# CY8C5868AXI_LP032 register map
File version: 0.1
CY8C58LP
Registers are 8-bit, read-write, no defined reset value unless marked. A register's access mark holds for its fields unless they carry their own. Offsets are from the block's base; lines under a group give offsets from that group; [hi:lo] are bit positions; {n}, {i} and the like mark numbered series; 'fields as' and 'values as' point back to an identical list; <NAME> marks a mode.

## Memory map
0x00000000 WDT_detect_com_err
0x00000000 Timer_PWM
0x00000000 Timer_cycle
0x00000000 USBUART_1 — USBFS
0x00000000 Timer_sub_cycle
0x00000000 ADC_SAR_1 — SAR ADC
0x00000000 VDAC8_1
0x40006460 BMP_SW
0x40006472 motor_en_reg
0x40006473 motor_contl_reg_1
0x40006476 SS0_B
0x4000647E motor_contl_reg_0

## motor_contl_reg_1
Base 0x40006473
0x00 motor_contl_reg_1_CONTROL_REG

## motor_en_reg
Base 0x40006472
Registers as motor_contl_reg_1 (with motor_contl_reg_1 read as motor_en_reg).

## motor_contl_reg_0
Base 0x4000647E
Registers as motor_contl_reg_1 (with motor_contl_reg_1 read as motor_contl_reg_0).

## SS0_B
Base 0x40006476
Registers as motor_contl_reg_1 (with motor_contl_reg_1 read as SS0_B).

## BMP_SW
Base 0x40006460
0x00 BMP_SW_STATUS_REG
0x20 BMP_SW_MASK_REG
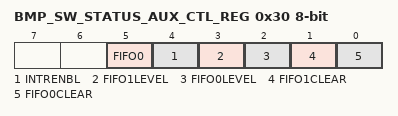
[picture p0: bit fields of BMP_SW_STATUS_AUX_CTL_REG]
0x30 BMP_SW_STATUS_AUX_CTL_REG
  [5] FIFO0 — FIFO0 clear
    1=ENABLED (Enable counter); 0=DISABLED (Disable counter)
  [4] INTRENBL — Enables or disables the Interrupt
    1=ENABLED (Interrupt enabled); 0=DISABLED (Interrupt disabled)
  [3] FIFO1LEVEL — FIFO level
    1=ENABLED (FIFO LVL: input mode: FIFO at least 1/2 empty; output mode: FIFO at least 1/2 full); 0=DISABLED (FIFO LVL: input mode: FIFO not full; output mode: FIFO not empty)
  [2] FIFO0LEVEL — FIFO level
    values as FIFO1LEVEL
  [1] FIFO1CLEAR — FIFO clear
    1=ENABLED (Clear FIFO state); 0=DISABLED (Normal FIFO operation)
  [0] FIFO0CLEAR — FIFO clear
    values as FIFO1CLEAR

## WDT_detect_com_err
Base 0x00000000
0x40006400 WDT_detect_com_err_COUNTER 16-bit — UDB.A0 - Current Down Counter Value
0x40006420 WDT_detect_com_err_PERIOD 16-bit — UDB.D0 - Assigned Period
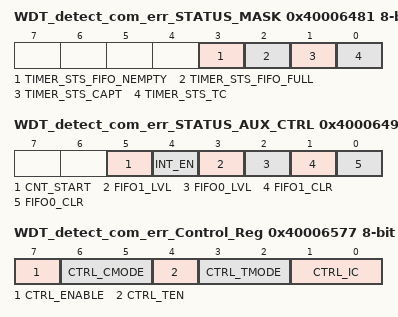
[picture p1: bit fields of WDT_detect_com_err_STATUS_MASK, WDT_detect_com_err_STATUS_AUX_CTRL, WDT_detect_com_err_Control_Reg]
0x40006481 WDT_detect_com_err_STATUS_MASK — UDB Status bits Interrupt Mask Enable Register
  [3] TIMER_STS_FIFO_NEMPTY ro — FIFO Empty status
  [2] TIMER_STS_FIFO_FULL ro — FIFO Full Status
  [1] TIMER_STS_CAPT ro — Enables the Interrupt on Capture
  [0] TIMER_STS_TC ro — Enables the Interrupt on TC
0x40006491 WDT_detect_com_err_STATUS_AUX_CTRL — UDB Auxilliary Control Register
  [5] CNT_START — FIFO0 clear
    0=E_CNT_START0 (Disable counter); 1=E_CNT_START1 (Enable counter)
  [4] INT_EN
    0=E_INT_EN0 (Interrupt disabled); 1=E_INT_EN1 (Interrupt enabled)
  [3] FIFO1_LVL — FIFO level
    0=E_FIFO_LVL_0 (FIFO LVL: input mode: FIFO not full; output mode: FIFO not empty); 1=E_FIFO_LVL_1 (FIFO LVL: input mode: FIFO at least 1/2 empty; output mode: FIFO at least 1/2 full)
  [2] FIFO0_LVL — FIFO level
    values as FIFO1_LVL
  [1] FIFO1_CLR — FIFO1 clear
    0=E_FIFO_CLR_0 (Normal FIFO operation); 1=E_FIFO_CLR_1 (Clear FIFO state)
  [0] FIFO0_CLR — FIFO0 clear
    values as FIFO1_CLR
0x40006577 WDT_detect_com_err_Control_Reg — UDB Control Register - Assigned Control Register Value
  [7] CTRL_ENABLE — Enable the Timer
  [6:5] CTRL_CMODE — Capture Mode
  [4] CTRL_TEN — Trigger Enable Bit
  [3:2] CTRL_TMODE — Trigger Mode
  [1:0] CTRL_IC — Interrupt Count

## Timer_PWM
Base 0x00000000
0x40006403 Timer_PWM_COUNTER — UDB.A0 - Current Down Counter Value
0x40006423 Timer_PWM_PERIOD — UDB.D0 - Assigned Period
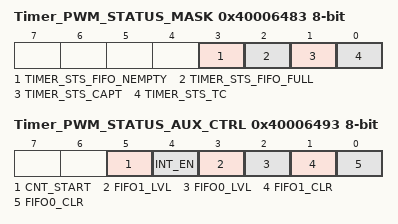
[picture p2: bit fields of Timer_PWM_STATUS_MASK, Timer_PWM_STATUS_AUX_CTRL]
0x40006483 Timer_PWM_STATUS_MASK — UDB Status bits Interrupt Mask Enable Register
  [3] TIMER_STS_FIFO_NEMPTY ro — FIFO Empty status
  [2] TIMER_STS_FIFO_FULL ro — FIFO Full Status
  [1] TIMER_STS_CAPT ro — Enables the Interrupt on Capture
  [0] TIMER_STS_TC ro — Enables the Interrupt on TC
0x40006493 Timer_PWM_STATUS_AUX_CTRL — UDB Auxilliary Control Register
  [5] CNT_START — FIFO0 clear
    0=E_CNT_START0 (Disable counter); 1=E_CNT_START1 (Enable counter)
  [4] INT_EN
    0=E_INT_EN0 (Interrupt disabled); 1=E_INT_EN1 (Interrupt enabled)
  [3] FIFO1_LVL — FIFO level
    0=E_FIFO_LVL_0 (FIFO LVL: input mode: FIFO not full; output mode: FIFO not empty); 1=E_FIFO_LVL_1 (FIFO LVL: input mode: FIFO at least 1/2 empty; output mode: FIFO at least 1/2 full)
  [2] FIFO0_LVL — FIFO level
    values as FIFO1_LVL
  [1] FIFO1_CLR — FIFO1 clear
    0=E_FIFO_CLR_0 (Normal FIFO operation); 1=E_FIFO_CLR_1 (Clear FIFO state)
  [0] FIFO0_CLR — FIFO0 clear
    values as FIFO1_CLR
